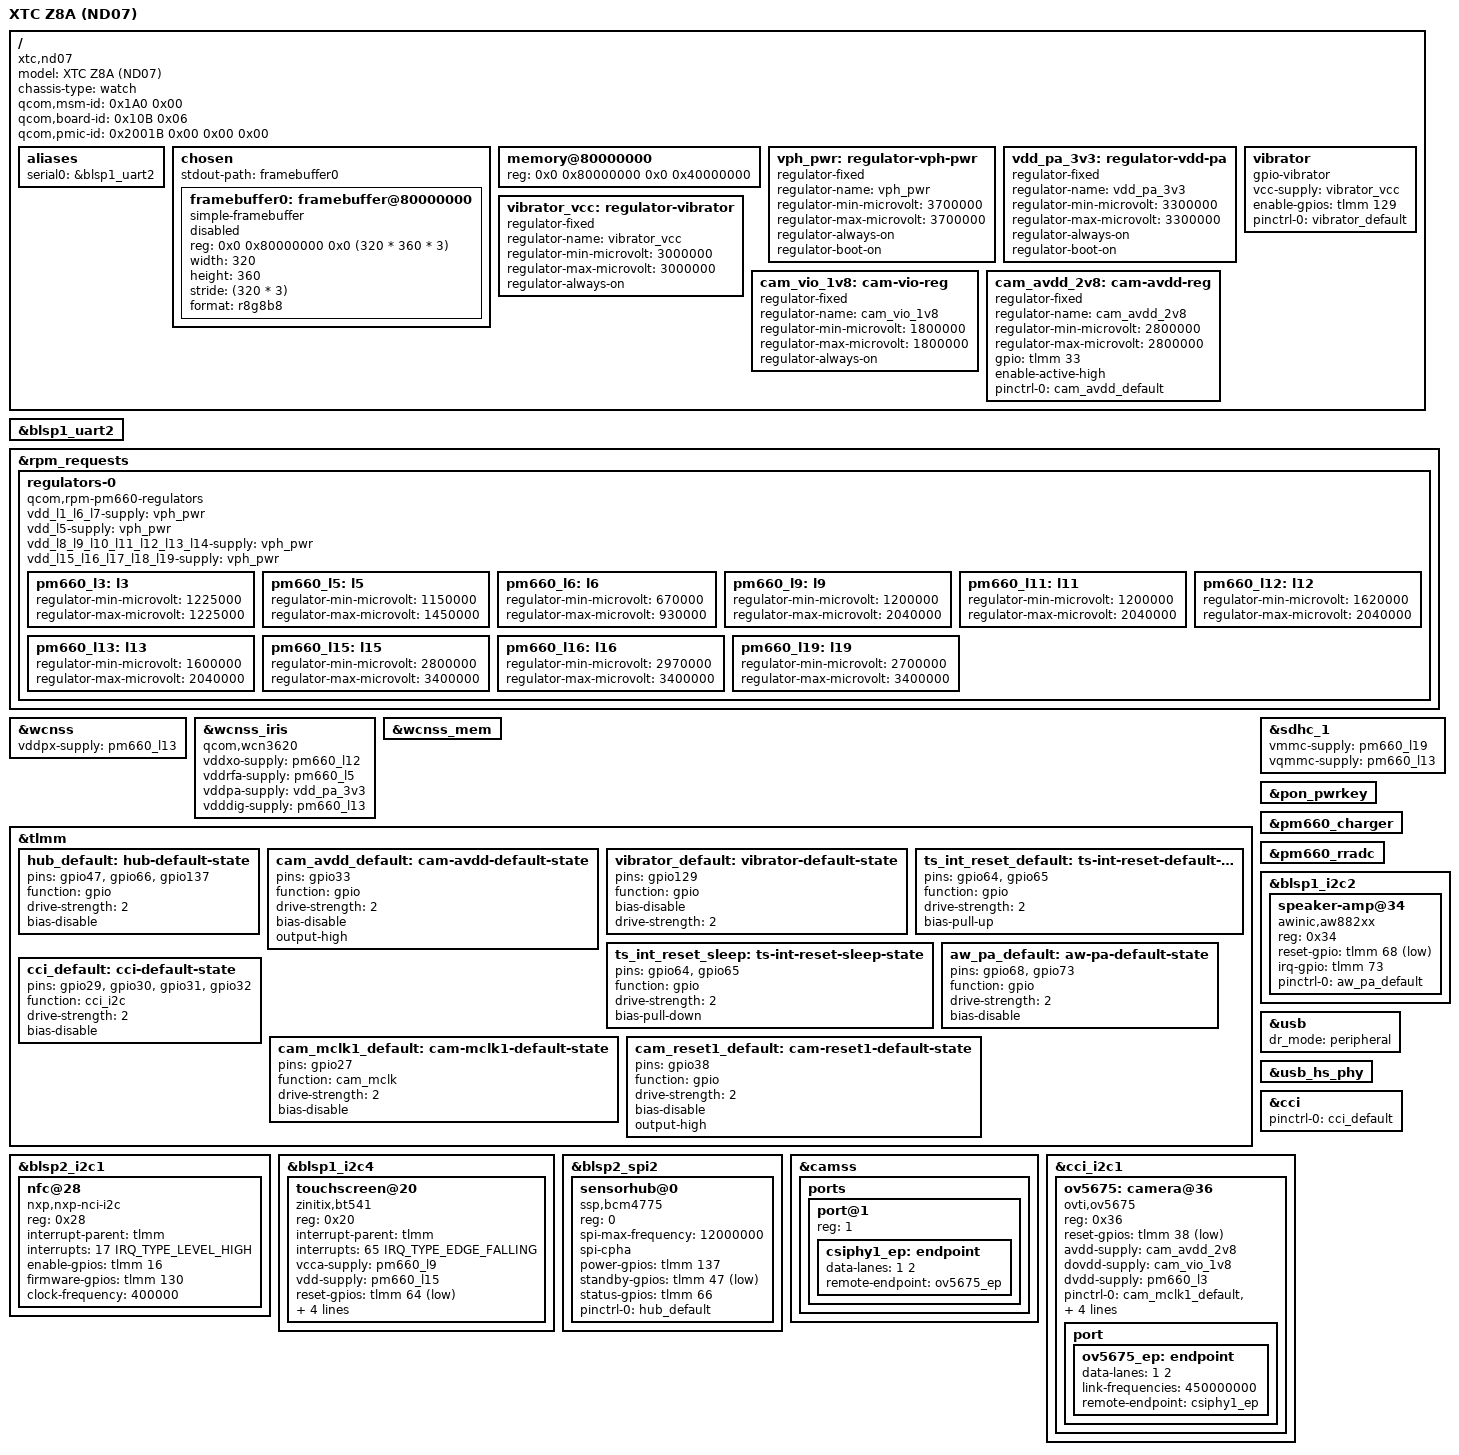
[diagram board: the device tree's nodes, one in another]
// SPDX-License-Identifier: BSD-3-Clause
/*
 * XTC Z8A (machine code ND07) - Snapdragon Wear 4100+ (SDM429W)
 *
 * SDM429W is an msm8937 derivative for Wear OS. This tree is the first
 * bring-up: get a mainline kernel far enough to print on the panel and
 * spawn a shell. The PM660 regulator tree is modelled below; storage, USB
 * and touch are not wired up yet.
 *
 * The framebuffer is handed over by lk2nd (cont-splash): it fills in reg,
 * width, height, stride, format and flips status to "okay" before booting.
 * status is "disabled" here so that a boot without that handover does not
 * scribble over random RAM.
 */

/dts-v1/;

#include <dt-bindings/clock/qcom,gcc-msm8917.h>
#include <dt-bindings/gpio/gpio.h>
#include <dt-bindings/interrupt-controller/irq.h>
#include <dt-bindings/input/input.h>

#include "msm8937.dtsi"
#include "pm660.dtsi"

/ {
	model = "XTC Z8A (ND07)";
	compatible = "xtc,nd07", "qcom,msm8937";
	chassis-type = "watch";

	/*
	 * Read back from the stock system at /proc/device-tree/. LK only ever
	 * compares the first entry of each property, so keep them single-entry.
	 */
	qcom,msm-id = <0x1A0 0x00>;
	qcom,board-id = <0x10B 0x06>;
	qcom,pmic-id = <0x2001B 0x00 0x00 0x00>;

	aliases {
		serial0 = &blsp1_uart2;
	};

	chosen {
		#address-cells = <2>;
		#size-cells = <2>;
		ranges;
		stdout-path = "framebuffer0";

		framebuffer0: framebuffer@80000000 {
			compatible = "simple-framebuffer";
			reg = <0x0 0x80000000 0x0 (320 * 360 * 3)>;
			width = <320>;
			height = <360>;
			stride = <(320 * 3)>;
			format = "r8g8b8";
			status = "disabled";

			/*
			 * Deliberately no clocks / power-domains here: lk2nd already
			 * brought MDSS and the panel up and keeps scanning out of this
			 * buffer. Listing them would make simpledrm defer until the
			 * GCC/RPM clock controller probes, which needs SMEM and may
			 * never happen during bring-up - and then we would have no
			 * console at all.
			 */
		};
	};

	memory@80000000 {
		device_type = "memory";
		reg = <0x0 0x80000000 0x0 0x40000000>;
	};
};

/*
 * Board-level fixed rails.
 *
 * vph_pwr is the battery/VPH_PWR input. The stock DT does not describe it (the
 * vendor RPM regulator driver does not need a parent tree), but mainline's
 * regulator core wants a supplier for the PMIC LDO inputs and for the
 * fixed-regulator style rails, so it is modelled here. 3.7 V nominal is what
 * every other msm8937/msm8916 board uses.
 *
 * vdd_pa_3v3 is the WCN3620 PA rail. IMPORTANT: this is the one rail we could
 * NOT confirm. The vendor DT node /soc/qcom,wcnss-wlan@0a000000 carries
 * qcom,pronto-vddpx/vddcx/vddmx and qcom,iris-vddxo/vddrfa/vdddig supplies, but
 * there is no qcom,iris-vddpa-supply, and
 * /sys/kernel/debug/regulator/regulator_summary lists exactly three PM660 rails
 * with a wcnss consumer (l5, l12 and l13 twice). So the stock kernel never
 * touches a PA rail: it is either always on from a PM660L output (not present
 * in the vendor DT at all) or a fixed path from VPH_PWR. Modelling it as an
 * always-on 3.3 V fixed regulator lets qcom_wcnss_iris probe succeed without
 * claiming control of a rail we cannot see - it is never gated and never
 * reprogrammed. Needs schematic confirmation.
 */
/ {
	vph_pwr: regulator-vph-pwr {
		compatible = "regulator-fixed";
		regulator-name = "vph_pwr";
		regulator-min-microvolt = <3700000>;
		regulator-max-microvolt = <3700000>;
		regulator-always-on;
		regulator-boot-on;
	};

	vdd_pa_3v3: regulator-vdd-pa {
		compatible = "regulator-fixed";
		regulator-name = "vdd_pa_3v3";
		regulator-min-microvolt = <3300000>;
		regulator-max-microvolt = <3300000>;
		regulator-always-on;
		regulator-boot-on;
	};
};

&blsp1_uart2 {
	status = "okay";
};

/*
 * PM660 regulators, RPM/SMD managed: the RPM owns the PMIC over SPMI and the AP
 * only sends resource requests (qcom,rpm-smd -> rpm-regulator-ldoaN), so these
 * are "qcom,rpm-pm660-regulators" and not SPMI regulators. This matches what
 * the stock DT does: /soc/qcom,rpm-smd has children rpm-regulator-ldoa1..19 and
 * rpm-regulator-smpa1..6.
 *
 * The min/max pairs are regulator-min/max-microvolt copied verbatim from
 * /soc/qcom,rpm-smd/rpm-regulator-ldoaN/regulator-lN on the running device.
 * Each comment names the consumer and the voltage the stock kernel actually
 * runs the rail at, taken from /sys/kernel/debug/regulator/regulator_summary.
 * Avoid pinning min == max: mmc re-requests vmmc/vqmmc at 2.95-3.3 V / 1.8 V and
 * a too-narrow range makes card init fail.
 *
 * Only PM660 is modelled. The RPM resource set on the device is exactly PM660's
 * (no ldob/smpb/rwcx/rwmx/rwlc/rwlm/bobb), the SPMI bus only has USID 0 and 1,
 * and the word "pm660l" does not occur anywhere in the vendor DT, so including
 * pm660l.dtsi would create phantom SPMI devices for a chip the stock firmware
 * does not describe. Revisit if a schematic shows a real PM660L.
 */
&rpm_requests {
	regulators-0 {
		compatible = "qcom,rpm-pm660-regulators";
		/*
		 * LDO/SMPS input rails. The true parents are PM660L / BOB outputs
		 * that are invisible to us, so tie them to the battery rail. This
		 * only builds a parent link for constraint propagation; without a
		 * supplier the core defers the rail's probe forever and every
		 * consumer (WCNSS included) fails to get it.
		 */
		vdd_l1_l6_l7-supply = <&vph_pwr>;
		vdd_l5-supply = <&vph_pwr>;
		vdd_l8_l9_l10_l11_l12_l13_l14-supply = <&vph_pwr>;
		vdd_l15_l16_l17_l18_l19-supply = <&vph_pwr>;

		/*
		 * Camera core rail: vendor camera@1 cam_vdig is 1.225 V and
		 * its phandle resolves to PM660 LDO3.
		 */
		pm660_l3: l3 {
			regulator-min-microvolt = <1225000>;
			regulator-max-microvolt = <1225000>;
		};

		/* WCNSS iris vddrfa. Stock runs 1.15 V; iris may ask for 1.30 V. */
		pm660_l5: l5 {
			regulator-min-microvolt = <1150000>;
			regulator-max-microvolt = <1450000>;
		};

		/* USB HS phy dig (hsusb_vdd_dig) + MDSS vdda. Stock 0.80 V. */
		pm660_l6: l6 {
			regulator-min-microvolt = <670000>;
			regulator-max-microvolt = <930000>;
		};

		/* Touch vcc_i2c (I2C pull-ups), both panels. Stock 1.80 V. */
		pm660_l9: l9 {
			regulator-min-microvolt = <1200000>;
			regulator-max-microvolt = <2040000>;
		};

		/* Codec vdd_dig + AW8896 smart PA DVDD. Stock 1.20 V. */
		pm660_l11: l11 {
			regulator-min-microvolt = <1200000>;
			regulator-max-microvolt = <2040000>;
		};

		/*
		 * WCNSS vddxo, USB HSUSB_1p8, MSS and pronto PLL. Stock 1.80 V.
		 * GCC's vdd_hf_pll/vdd_sr2_pll use the always-on sibling
		 * (regulator-l12-ao), which mainline's RPM regulator driver does
		 * not model - it only knows the one "l12" resource.
		 */
		pm660_l12: l12 {
			regulator-min-microvolt = <1620000>;
			regulator-max-microvolt = <2040000>;
		};

		/*
		 * WCNSS vddpx and vdddig, eMMC vqmmc, panel/DSI vddio. Stock
		 * 1.80 V. Heavily shared (474 uses in stock) - never gate it.
		 */
		pm660_l13: l13 {
			regulator-min-microvolt = <1600000>;
			regulator-max-microvolt = <2040000>;
		};

		/* Touch AVDD + DSI VDD. Stock 2.80 V. */
		pm660_l15: l15 {
			regulator-min-microvolt = <2800000>;
			regulator-max-microvolt = <3400000>;
		};

		/* USB HSUSB_3p3. Stock 3.05 V. */
		pm660_l16: l16 {
			regulator-min-microvolt = <2970000>;
			regulator-max-microvolt = <3400000>;
		};

		/* eMMC VMMC. Stock 3.20 V. */
		pm660_l19: l19 {
			regulator-min-microvolt = <2700000>;
			regulator-max-microvolt = <3400000>;
		};
	};
};

/*
 * WCNSS (Wi-Fi/BT). SDM429W uses the pronto-v3 firmware loader with an
 * external "iris" RF chip. Everything device-independent (CCU/DXE/PMU
 * register blocks, wdog + smp2p interrupts, the pronto smd-edge,
 * WCNSS_CTRL, and the wcnss-wlan tx/rx SPIs 145/146 with the apps_smsm
 * 9/10 states) is inherited from msm8937.dtsi; only board bits here.
 *
 * Read back from the vendor DT (/soc/qcom,wcnss-wlan@0a000000):
 *     qcom,is-pronto-v3; qcom,has-pronto-hw; qcom,has-autodetect-xo
 *     interrupts = <0 0x91 0>, <0 0x92 0>        -> tx, rx
 * and the supply phandles, resolved against the RPM regulator nodes:
 *     qcom,pronto-vddpx-supply  -> pm660_l13   1.8 V
 *     qcom,iris-vddxo-supply    -> pm660_l12   1.8 V
 *     qcom,iris-vddrfa-supply   -> pm660_l5    1.15 V
 *     qcom,iris-vdddig-supply   -> pm660_l13   1.8 V
 *     qcom,pronto-vddcx/vddmx   -> CX/MX corners, handled by rpmpd
 * qcom,iris-vddpa is absent on this board; see vdd_pa_3v3 above.
 *
 * The matching mainline iris is qcom,wcn3620 (19.2 MHz XO, 1.8 V vddxo and
 * vdddig, 3.3 V vddpa), as on the other pronto-v3 msm8937 boards
 * (msm8937-xiaomi-land.dts, msm8917-xiaomi-riva.dts). pronto_v3_data in
 * qcom_wcnss.c only bulk-gets "vddpx" (CX/MX come from power-domains), so all
 * five supplies below have to resolve or devm_regulator_bulk_get() fails.
 */
&wcnss {
	vddpx-supply = <&pm660_l13>;

	status = "okay";
};

&wcnss_iris {
	compatible = "qcom,wcn3620";

	vddxo-supply = <&pm660_l12>;
	vddrfa-supply = <&pm660_l5>;
	vddpa-supply = <&vdd_pa_3v3>;
	vdddig-supply = <&pm660_l13>;
};

&wcnss_mem {
	status = "okay";
};

/*
 * Haptic motor. The stock kernel has a private "xtc_vibrator" driver that
 * hardcodes the GPIO; the DT only carries a pinctrl handle. Pin function and
 * drive strength below were read back from the running device:
 *     /soc/pinctrl@1000000/xtc_vibrator_pin
 *         mux    { pins = "gpio129"; function = "gpio"; }
 *         config { pins = "gpio129"; bias-disable; drive-strength = <2>; }
 * Mainline gpio-vibrator covers this, so no custom driver is needed.
 */
/ {
	vibrator_vcc: regulator-vibrator {
		compatible = "regulator-fixed";
		regulator-name = "vibrator_vcc";
		regulator-min-microvolt = <3000000>;
		regulator-max-microvolt = <3000000>;
		regulator-always-on;
	};

	vibrator {
		compatible = "gpio-vibrator";
		vcc-supply = <&vibrator_vcc>;
		enable-gpios = <&tlmm 129 GPIO_ACTIVE_HIGH>;
		pinctrl-names = "default";
		pinctrl-0 = <&vibrator_default>;
	};
};

&tlmm {

	hub_default: hub-default-state {
		pins = "gpio47", "gpio66", "gpio137";
		function = "gpio";
		drive-strength = <2>;
		bias-disable;
	};

	cam_avdd_default: cam-avdd-default-state {
		pins = "gpio33";
		function = "gpio";
		drive-strength = <2>;
		bias-disable;
		output-high;
	};
	vibrator_default: vibrator-default-state {
		pins = "gpio129";
		function = "gpio";
		bias-disable;
		drive-strength = <2>;
	};
};

/*
 * NXP NQ-series NFC controller on BLSP2 QUP1.
 * Pin map read back from the vendor DT node /soc/i2c@7af5000/nq@28:
 *     qcom,nq-irq  = <&tlmm 17 0>
 *     qcom,nq-ven  = <&tlmm 16 0>
 *     qcom,nq-firm = <&tlmm 130 0>
 *     qcom,clk-src = "BBCLK2"
 * Mainline nxp-nci-i2c covers it.
 */
&blsp2_i2c1 {
	status = "okay";

	nfc@28 {
		compatible = "nxp,nxp-nci-i2c";
		reg = <0x28>;
		interrupt-parent = <&tlmm>;
		interrupts = <17 IRQ_TYPE_LEVEL_HIGH>;
		enable-gpios = <&tlmm 16 GPIO_ACTIVE_HIGH>;
		firmware-gpios = <&tlmm 130 GPIO_ACTIVE_HIGH>;
		clock-frequency = <400000>;
	};
};

/*
 * eMMC (sdhc_1). Supply mapping read back from the vendor DT node
 * /soc/sdhci@7824900 (vdd -> pm660_l19, vdd-io -> pm660_l13) and confirmed by
 * regulator_summary. Only the supplies are wired here: keep the node disabled
 * until storage bring-up, then delete the status line.
 */
&sdhc_1 {
	vmmc-supply = <&pm660_l19>;
	vqmmc-supply = <&pm660_l13>;
	status = "okay";
};

/*
 * Power key. pm660.dtsi brings a PON block with a pm8941-pwrkey child that
 * already carries linux,code = <KEY_POWER>; it is "disabled" there because it
 * is a per-board choice. The stock DT confirms the mapping: the qpnp-power-on
 * node has interrupt-names kpdpwr/resin/... and its qcom,pon_1 child (PON type 0
 * = KPDPWR) has linux,code = 116 = KEY_POWER, while qcom,pon_2 (resin) is 114 =
 * KEY_VOLUMEDOWN. Only the power key is enabled here.
 */
&pon_pwrkey {
	status = "okay";
};

/*
 * Touch: Zinitix BT541 on BLSP1 QUP4 at 0x20.
 * Read back from the stock node /soc/i2c@78b8000/bt541_ts_device@20:
 *     zinitix,irq-gpio   = <&tlmm 65 0x08>
 *     zinitix,reset-gpio = <&tlmm 64 0>
 *     x_resolution = 319, y_resolution = 359  -> 320x360
 *     zinitix,pname = "SM-G5308W"
 * Supplies resolved by the regulator audit: vcc_i2c -> pm660_l9 (1.8 V),
 * vdd -> pm660_l15 (2.8 V).
 * Mainline zinitix.c already lists "zinitix,bt541", so this is DT only.
 */
&blsp1_i2c4 {
	status = "okay";

	touchscreen@20 {
		compatible = "zinitix,bt541";
		reg = <0x20>;

		interrupt-parent = <&tlmm>;
		interrupts = <65 IRQ_TYPE_EDGE_FALLING>;

		vcca-supply = <&pm660_l9>;
		vdd-supply = <&pm660_l15>;

		reset-gpios = <&tlmm 64 GPIO_ACTIVE_LOW>;

		pinctrl-names = "default", "sleep";
		pinctrl-0 = <&ts_int_reset_default>;
		pinctrl-1 = <&ts_int_reset_sleep>;

		touchscreen-size-x = <320>;
		touchscreen-size-y = <360>;
	};
};

&tlmm {
	ts_int_reset_default: ts-int-reset-default-state {
		pins = "gpio64", "gpio65";
		function = "gpio";
		drive-strength = <2>;
		bias-pull-up;
	};

	ts_int_reset_sleep: ts-int-reset-sleep-state {
		pins = "gpio64", "gpio65";
		function = "gpio";
		drive-strength = <2>;
		bias-pull-down;
	};
};

/*
 * Sensor hub: Broadcom BCM4775 on BLSP2 QUP3 (spi@7af6000), chip select 0.
 * The vendor node is /soc/spi@7af6000/bcm4775@0 with
 *     compatible = "ssp,bcm4775"
 *     reg = <0>, spi-max-frequency = <1817344>
 * "ssp" is Samsung's Sensor Sub-Processor protocol, and mainline already
 * carries a framework for it in drivers/iio/common/ssp_sensors/.
 *
 * NOTE: the stock node exposes neither interrupts nor the mcu-ap/ap-mcu
 * handshake GPIOs that ssp_dev.c currently requires, so the framework needs
 * a BCM4775 quirk (sensor list + optional handshake) before this can bind.
 */
&blsp2_spi2 {
	status = "okay";

	/*
	 * Values read from the vendor node, which spells the cells out:
	 *   gps,power_enable = <&tlmm 0x89 0>  -> GPIO 137
	 *   gps-nstandby     = <&tlmm 0x2f 0>  -> GPIO 47
	 *   ap-status        = <&tlmm 0x42 0>  -> GPIO 66
	 *   spi-max-frequency = 0x00b71b00     -> 12 MHz
	 * plus spi-cpha, i.e. SPI mode 1.  The vendor calls the host side of
	 * this link "ttyBCM-SPI" (main-host-name), which is the same ttyBCM
	 * that shows up as an msmgpio interrupt on the stock kernel.
	 */
	sensorhub@0 {
		compatible = "ssp,bcm4775";
		reg = <0>;

		spi-max-frequency = <12000000>;
		spi-cpha;

		power-gpios = <&tlmm 137 GPIO_ACTIVE_HIGH>;
		standby-gpios = <&tlmm 47 GPIO_ACTIVE_LOW>;
		status-gpios = <&tlmm 66 GPIO_ACTIVE_HIGH>;

		pinctrl-names = "default";
		pinctrl-0 = <&hub_default>;
	};
};

/*
 * Charger + RRADC. pm660.dtsi already describes charger@1000 with
 * compatible "qcom,pm660-charger" (matched by mainline qcom_smbx.c) and
 * adc@4500 as "qcom,pm660-rradc".  The charger needs the RRADC for the
 * usbin_v/usbin_i channels that back VOLTAGE_NOW and CURRENT_NOW, so both
 * get enabled together.
 *
 * The vendor node was "qcom,qpnp-smb2" with no interrupts property; the
 * mainline driver polls, which is why no IRQ wiring is needed here.
 */
&pm660_charger {
	status = "okay";
};

&pm660_rradc {
	status = "okay";
};

/*
 * Speaker amplifier. The part on the board reports chip id 0x2113, i.e. an
 * Awinic AW88261, but it is wired without any regulator at all: the vendor
 * driver calls no regulator API, and the vendor DT node carries no supply.
 * That is why this uses the aw882xx driver rather than the in-tree
 * aw88261.c, which unconditionally enables a "dvdd" supply.
 *
 * Vendor node /soc/i2c@78b6000/aw882xx_smartpa@34:
 *     reg = <0x34>, reset-gpio = <&tlmm 68 0>, irq-gpio = <&tlmm 73 0>
 * The codec is an I2S clock/frame consumer, so the CPU DAI has to be the
 * bitclock and frame master.
 */
&blsp1_i2c2 {
	status = "okay";

	speaker-amp@34 {
		compatible = "awinic,aw882xx";
		reg = <0x34>;

		reset-gpio = <&tlmm 68 GPIO_ACTIVE_LOW>;
		irq-gpio = <&tlmm 73 GPIO_ACTIVE_HIGH>;

		pinctrl-names = "default";
		pinctrl-0 = <&aw_pa_default>;
	};
};

&tlmm {
	aw_pa_default: aw-pa-default-state {
		pins = "gpio68", "gpio73";
		function = "gpio";
		drive-strength = <2>;
		bias-disable;
	};
};

/*
 * USB. The watch uses a ChipIdea HDRC (qcom,ci-hdrc) with a 28nm femto HS
 * PHY, both already described in msm8937.dtsi but disabled.  Force
 * peripheral mode so the port comes up as a gadget: this is the debug
 * console, so RNDIS/ACM can be exposed through configfs.
 */
&usb {
	status = "okay";
	dr_mode = "peripheral";
};

&usb_hs_phy {
	status = "okay";
};

/*
 * Cameras.
 *
 * The watch has two camera slots; only the front one has a mainline driver:
 *
 *   slot 0 (rear)  sc520cs_TSP  CCI master 0, CSIPHY0/CSID0, MCLK0 = GPIO 26
 *   slot 1 (front) ov5675_TSP   CCI master 1, CSIPHY1/CSID1, MCLK1 = GPIO 27
 *
 * Values below come from the merged device tree read off the running device
 * (/sys/firmware/devicetree/base/soc/qcom,cci@1b0c000/qcom,camera@1):
 *
 *   gpios        = <26 36 58>  -> CAMIF_MCLK0, CAM_RESET0, CAM_VANA0
 *   qcom,cci-master = <1>, qcom,csiphy-sd-index = <1>, qcom,csid-sd-index = <1>
 *   qcom,clock-rates = <24000000 0>
 *   qcom,cam-vreg-name = "cam_vdig", "cam_vio"  (1.225 V and 1.8 V)
 *
 * The rear sensor is not described here: there is no sc520cs driver in
 * mainline, and a DT node without a driver is dead weight.
 */
&camss {
	status = "okay";

	ports {
		port@1 {
			reg = <1>;

			csiphy1_ep: endpoint {
				data-lanes = <1 2>;
				remote-endpoint = <&ov5675_ep>;
			};
		};
	};
};

&cci {
	status = "okay";
	pinctrl-names = "default";
	pinctrl-0 = <&cci_default>;
};

&cci_i2c1 {
	/*
	 * The sensor's I2C address is not in the vendor device tree (the
	 * downstream driver hardcodes it), so 0x36 -- the OV5675 default and
	 * what mainline uses elsewhere -- is assumed and still needs to be
	 * confirmed on hardware.
	 *
	 * Supplies: the vendor node asks for cam_vdig (1.225 V) and cam_vio
	 * (1.8 V); cam_vdig resolves to PM660 LDO3, which this board file does
	 * not model yet, and cam_vio's phandle does not resolve to any
	 * enumerable regulator node at all.  Rather than invent labels, the
	 * supplies are omitted -- so this node will not probe until the rails
	 * are added.  avdd (2.8 V) is behind the CAM_AVDD1 enable on GPIO 33
	 * and is missing for the same reason.
	 */
	ov5675: camera@36 {
		compatible = "ovti,ov5675";
		reg = <0x36>;

		reset-gpios = <&tlmm 38 GPIO_ACTIVE_LOW>;
		avdd-supply = <&cam_avdd_2v8>;
		dovdd-supply = <&cam_vio_1v8>;
		dvdd-supply = <&pm660_l3>;
		pinctrl-names = "default";
		pinctrl-0 = <&cam_mclk1_default>, <&cam_reset1_default>;

		/*
		 * The vendor tree clocks this sensor at 24 MHz.  Mainline's
		 * ov5675 driver only knows a 19.2 MHz XVCLK (its PLL tables are
		 * written for it), and GCC can generate 19.2 MHz from XO, so
		 * that is what is requested here.  If the module turns out to
		 * need a real 24 MHz, the driver needs a second PLL table.
		 */
		clocks = <&gcc GCC_CAMSS_MCLK1_CLK>;
		assigned-clocks = <&gcc GCC_CAMSS_MCLK1_CLK>;
		assigned-clock-rates = <19200000>;

		port {
			ov5675_ep: endpoint {
				data-lanes = <1 2>;
				link-frequencies = /bits/ 64 <450000000>;
				remote-endpoint = <&csiphy1_ep>;
			};
		};
	};
};

&tlmm {
	/* CCI master 0 on GPIO 29/30, master 1 on GPIO 31/32. */
	cci_default: cci-default-state {
		pins = "gpio29", "gpio30", "gpio31", "gpio32";
		function = "cci_i2c";
		drive-strength = <2>;
		bias-disable;
	};

	cam_mclk1_default: cam-mclk1-default-state {
		pins = "gpio27";
		function = "cam_mclk";
		drive-strength = <2>;
		bias-disable;
	};

	cam_reset1_default: cam-reset1-default-state {
		pins = "gpio38";
		function = "gpio";
		drive-strength = <2>;
		bias-disable;
		output-high;
	};
};

/ {
/*
 * Camera I/O rail. The vendor tree points cam_vio at a phandle that resolves
 * to nothing, so this is modelled as an always-on 1.8 V supply: the rail is
 * shared with the rest of the board and never gated in the vendor driver.
 */
cam_vio_1v8: cam-vio-reg {
	compatible = "regulator-fixed";
	regulator-name = "cam_vio_1v8";
	regulator-min-microvolt = <1800000>;
	regulator-max-microvolt = <1800000>;
	regulator-always-on;
};

/*
 * Camera analog rail, switched by CAM_AVDD1 on TLMM 33 (vendor camera@1
 * lists gpio-vana = 1 -> GPIO33 and carries no avdd supply of its own, i.e.
 * it is a switch, not a regulator).
 */
cam_avdd_2v8: cam-avdd-reg {
	compatible = "regulator-fixed";
	regulator-name = "cam_avdd_2v8";
	regulator-min-microvolt = <2800000>;
	regulator-max-microvolt = <2800000>;
	gpio = <&tlmm 33 GPIO_ACTIVE_HIGH>;
	enable-active-high;
	pinctrl-names = "default";
	pinctrl-0 = <&cam_avdd_default>;
};
};
